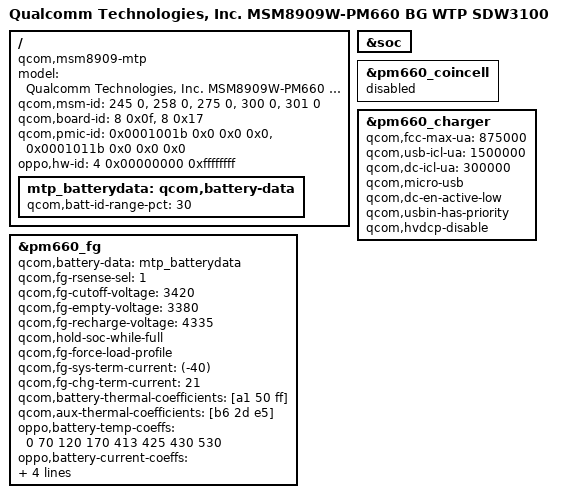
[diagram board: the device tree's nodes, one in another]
/* Copyright (c) 2017-2018, The Linux Foundation. All rights reserved.
 *
 * This program is free software; you can redistribute it and/or modify
 * it under the terms of the GNU General Public License version 2 and
 * only version 2 as published by the Free Software Foundation.
 *
 * This program is distributed in the hope that it will be useful,
 * but WITHOUT ANY WARRANTY; without even the implied warranty of
 * MERCHANTABILITY or FITNESS FOR A PARTICULAR PURPOSE.  See the
 * GNU General Public License for more details.
 */


#include "sdw3100-msm8909w-oppo-common.dtsi"

/ {
	model = "Qualcomm Technologies, Inc. MSM8909W-PM660 BG WTP SDW3100";
	compatible = "qcom,msm8909-mtp", "qcom,msm8909", "qcom,mtp";
	qcom,msm-id =   <245 0>,
			<258 0>,
			<275 0>,
			<300 0>,
			<301 0>;
	qcom,board-id = <8 0x0f>,
			<8 0x17>;
	qcom,pmic-id =  <0x0001001b 0x0 0x0 0x0>,
			<0x0001011b 0x0 0x0 0x0>;
	oppo,hw-id = <4 0x00000000 0xffffffff>;
};


&soc {


};

/ {
	/delete-node/ qcom,battery-data;
	mtp_batterydata: qcom,battery-data {
		qcom,batt-id-range-pct = <30>;
		#include "fg-gen3-batterydata-atl-opowx64-435mah.dtsi"
	};
};

&pm660_coincell {
	status = "disabled";
};

&pm660_charger {
	qcom,fcc-max-ua = <875000>;
	qcom,usb-icl-ua = <1500000>;
	qcom,dc-icl-ua = <300000>;
	qcom,micro-usb;
	/*qcom,float-option = <2>;*/
	qcom,dc-en-active-low;
	qcom,usbin-has-priority;
	qcom,hvdcp-disable;
};

&pm660_fg {
	qcom,battery-data = <&mtp_batterydata>;

	qcom,fg-rsense-sel = <1>;	/* External rsense */
	qcom,fg-cutoff-voltage = <3420>;
        qcom,fg-empty-voltage = <3380>;
	qcom,fg-recharge-voltage = <4335>;

	qcom,hold-soc-while-full;
	qcom,fg-force-load-profile;
	qcom,fg-sys-term-current = <(-40)>;
	qcom,fg-chg-term-current = <21>;
	/* qcom,fg-use-sw-esr; */
	/* qcom,fg-esr-pulse-thresh-ma = <40>; */
	/* qcom,fg-esr-meas-curr-ma = <60>; */

	/* BETA=3435 */
	qcom,battery-thermal-coefficients = [a1 50 ff];

	/* BETA=4250 */
	qcom,aux-thermal-coefficients = [b6 2d e5];
        oppo,battery-temp-coeffs = <0 70 120 170 413 425 430 530>;
        oppo,battery-current-coeffs = <0 175000 250000 375000 875000 425000 425000 100000>;
        oppo,battery-rechg-mv-coeffs = <4035 4235 4335>;
        oppo,battery-max-mv-coeffs = <4135000 4435000>;
        oppo,oppo-current-ctl = <100000>;
};
